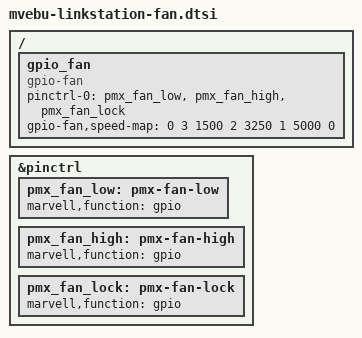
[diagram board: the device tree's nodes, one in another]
/ {
	gpio_fan {
		compatible = "gpio-fan";
		pinctrl-0 = <&pmx_fan_low &pmx_fan_high &pmx_fan_lock>;
		pinctrl-names = "default";
		gpio-fan,speed-map =
			<0		3
			1500	2
			3250	1
			5000	0>;
	};
};
&pinctrl {
	pmx_fan_low: pmx-fan-low {
		marvell,function = "gpio";
	};
	pmx_fan_high: pmx-fan-high {
		marvell,function = "gpio";
	};
	pmx_fan_lock: pmx-fan-lock {
		marvell,function = "gpio";
	};
};
